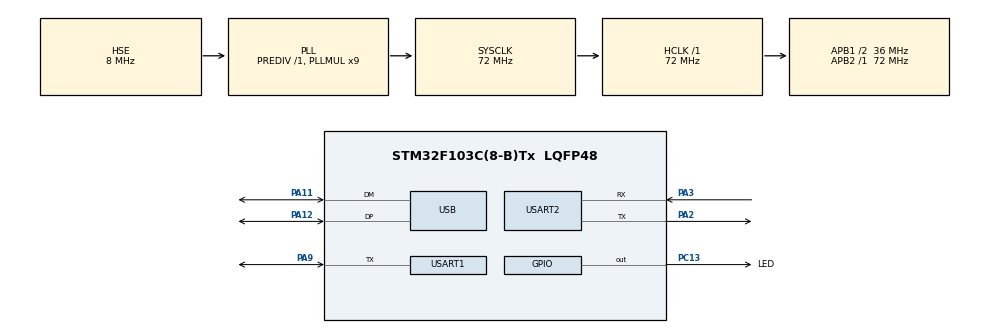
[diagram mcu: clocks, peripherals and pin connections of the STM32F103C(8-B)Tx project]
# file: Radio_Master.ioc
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Dma.Request0=USART1_RX
Dma.Request1=USART1_TX
Dma.USART1_RX.0.Direction=DMA_PERIPH_TO_MEMORY
Dma.USART1_RX.0.Instance=DMA1_Channel5
Dma.USART1_RX.0.MemDataAlignment=DMA_MDATAALIGN_BYTE
Dma.USART1_RX.0.MemInc=DMA_MINC_ENABLE
Dma.USART1_RX.0.Mode=DMA_CIRCULAR
Dma.USART1_RX.0.PeriphDataAlignment=DMA_PDATAALIGN_BYTE
Dma.USART1_RX.0.PeriphInc=DMA_PINC_DISABLE
Dma.USART1_RX.0.Priority=DMA_PRIORITY_LOW
Dma.USART1_TX.1.Direction=DMA_MEMORY_TO_PERIPH
Dma.USART1_TX.1.Instance=DMA1_Channel4
Dma.USART1_TX.1.MemDataAlignment=DMA_MDATAALIGN_BYTE
Dma.USART1_TX.1.MemInc=DMA_MINC_ENABLE
Dma.USART1_TX.1.Mode=DMA_NORMAL
Dma.USART1_TX.1.PeriphDataAlignment=DMA_PDATAALIGN_BYTE
Dma.USART1_TX.1.PeriphInc=DMA_PINC_DISABLE
Dma.USART1_TX.1.Priority=DMA_PRIORITY_LOW
FREERTOS.Tasks01=defaultTask,24,128,StartDefaultTask,Default,NULL,Dynamic,NULL,NULL;CRSF_task,8,128,CRSF_task_Entry,Default,NULL,Dynamic,NULL,NULL
FREERTOS.configUSE_NEWLIB_REENTRANT=1
Mcu.Family=STM32F1
Mcu.Name=STM32F103C(8-B)Tx
Mcu.Package=LQFP48
NVIC.DMA1_Channel4_IRQn=true\:5\:0\:false\:false\:true\:true\:false\:true\:true
NVIC.DMA1_Channel5_IRQn=true\:5\:0\:false\:false\:true\:true\:false\:true\:true
NVIC.PriorityGroup=NVIC_PRIORITYGROUP_4
NVIC.TIM2_IRQn=true\:15\:0\:false\:false\:true\:false\:false\:true\:true
NVIC.TimeBase=TIM2_IRQn
NVIC.TimeBaseIP=TIM2
NVIC.USART1_IRQn=true\:5\:0\:false\:false\:true\:true\:false\:true\:true
NVIC.USB_LP_CAN1_RX0_IRQn=true\:5\:0\:false\:false\:true\:true\:false\:true\:true
PA11.Mode=Device
PA11.Signal=USB_DM
PA12.Mode=Device
PA12.Signal=USB_DP
PA13.Mode=Serial_Wire
PA13.Signal=SYS_JTMS-SWDIO
PA14.Mode=Serial_Wire
PA14.Signal=SYS_JTCK-SWCLK
PA2.Mode=Asynchronous
PA2.Signal=USART2_TX
PA3.Mode=Asynchronous
PA3.Signal=USART2_RX
PA9.Mode=Half_duplex(single_wire_mode)
PA9.Signal=USART1_TX
PC13-TAMPER-RTC.GPIO_Label=LED
PC13-TAMPER-RTC.Signal=GPIO_Output
PC14-OSC32_IN.Mode=LSE-External-Oscillator
PC14-OSC32_IN.Signal=RCC_OSC32_IN
PC15-OSC32_OUT.Mode=LSE-External-Oscillator
PC15-OSC32_OUT.Signal=RCC_OSC32_OUT
PD0-OSC_IN.Mode=HSE-External-Oscillator
PD0-OSC_IN.Signal=RCC_OSC_IN
PD1-OSC_OUT.Mode=HSE-External-Oscillator
PD1-OSC_OUT.Signal=RCC_OSC_OUT
ProjectManager.HeapSize=0x200
ProjectManager.StackSize=0x400
ProjectManager.TargetToolchain=CMake
RCC.AHBFreq_Value=72000000
RCC.APB1CLKDivider=RCC_HCLK_DIV2
RCC.APB1Freq_Value=36000000
RCC.APB1TimFreq_Value=72000000
RCC.APB2Freq_Value=72000000
RCC.APB2TimFreq_Value=72000000
RCC.HCLKFreq_Value=72000000
RCC.PLLMUL=RCC_PLL_MUL9
RCC.SYSCLKFreq_VALUE=72000000
RCC.SYSCLKSource=RCC_SYSCLKSOURCE_PLLCLK
RCC.USBFreq_Value=48000000
RCC.USBPrescaler=RCC_USBCLKSOURCE_PLL_DIV1_5
USART1.BaudRate=400000
USART1.VirtualMode=VM_ASYNC
USART2.VirtualMode=VM_ASYNC
USB_DEVICE.CLASS_NAME_FS=CDC
USB_DEVICE.VirtualMode=Cdc
USB_DEVICE.VirtualModeFS=Cdc_FS
VP_FREERTOS_VS_CMSIS_V2.Mode=CMSIS_V2
VP_SYS_VS_tim2.Mode=TIM2
VP_USB_DEVICE_VS_USB_DEVICE_CDC_FS.Mode=CDC_FS
board=custom

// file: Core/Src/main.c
/* USER CODE BEGIN Header */
/**
  ******************************************************************************
  * @file           : main.c
  * @brief          : Main program body
  ******************************************************************************
  * @attention
  *
  * Copyright (c) 2026 STMicroelectronics.
  * All rights reserved.
  *
  * This software is licensed under terms that can be found in the LICENSE file
  * in the root directory of this software component.
  * If no LICENSE file comes with this software, it is provided AS-IS.
  *
  ******************************************************************************
  */
/* USER CODE END Header */
#include "main.h"
#include "cmsis_os.h"
#include "stm32f1xx_hal_gpio.h"
#include "usb_device.h"

/* USER CODE BEGIN Includes */
#include "crsf.h"
/* USER CODE END Includes */

UART_HandleTypeDef huart1;
UART_HandleTypeDef huart2;
DMA_HandleTypeDef hdma_usart1_rx;
DMA_HandleTypeDef hdma_usart1_tx;

/* Definitions for defaultTask */
osThreadId_t defaultTaskHandle;
const osThreadAttr_t defaultTask_attributes = {
  .name = "defaultTask",
  .stack_size = 128 * 4,
  .priority = (osPriority_t) osPriorityNormal,
};
/* Definitions for CRSF_task */
osThreadId_t CRSF_taskHandle;
const osThreadAttr_t CRSF_task_attributes = {
  .name = "CRSF_task",
  .stack_size = 256 * 4,
  .priority = (osPriority_t) osPriorityHigh,
};

void SystemClock_Config(void);
static void MX_GPIO_Init(void);
static void MX_DMA_Init(void);
static void MX_USART1_UART_Init(void);
static void MX_USART2_UART_Init(void);
void StartDefaultTask(void *argument);
void CRSF_task_Entry(void *argument);

int main(void)
{

  /* MCU Configuration--------------------------------------------------------*/

  /* Reset of all peripherals, Initializes the Flash interface and the Systick. */
  HAL_Init();

  /* Configure the system clock */
  SystemClock_Config();

  /* Initialize all configured peripherals */
  MX_GPIO_Init();
  MX_DMA_Init();
  MX_USART1_UART_Init();
  MX_USART2_UART_Init();

  /* Init scheduler */
  osKernelInitialize();

  /* Create the thread(s) */
  /* creation of defaultTask */
  defaultTaskHandle = osThreadNew(StartDefaultTask, NULL, &defaultTask_attributes);

  /* creation of CRSF_task */
  CRSF_taskHandle  = osThreadNew(CRSF_task_Entry,  NULL, &CRSF_task_attributes);

  /* Start scheduler */
  osKernelStart();

  /* We should never get here as control is now taken by the scheduler */

  /* Infinite loop */
  while (1)
  {

  }
}

void SystemClock_Config(void)
{
  RCC_OscInitTypeDef RCC_OscInitStruct = {0};
  RCC_ClkInitTypeDef RCC_ClkInitStruct = {0};
  RCC_PeriphCLKInitTypeDef PeriphClkInit = {0};

  /** Initializes the RCC Oscillators according to the specified parameters
  * in the RCC_OscInitTypeDef structure.
  */
  RCC_OscInitStruct.OscillatorType = RCC_OSCILLATORTYPE_HSE;
  RCC_OscInitStruct.HSEState = RCC_HSE_ON;
  RCC_OscInitStruct.HSEPredivValue = RCC_HSE_PREDIV_DIV1;
  RCC_OscInitStruct.HSIState = RCC_HSI_ON;
  RCC_OscInitStruct.PLL.PLLState = RCC_PLL_ON;
  RCC_OscInitStruct.PLL.PLLSource = RCC_PLLSOURCE_HSE;
  RCC_OscInitStruct.PLL.PLLMUL = RCC_PLL_MUL9;
  if (HAL_RCC_OscConfig(&RCC_OscInitStruct) != HAL_OK)
  {
    Error_Handler();
  }

  /** Initializes the CPU, AHB and APB buses clocks
  */
  RCC_ClkInitStruct.ClockType = RCC_CLOCKTYPE_HCLK|RCC_CLOCKTYPE_SYSCLK
                              |RCC_CLOCKTYPE_PCLK1|RCC_CLOCKTYPE_PCLK2;
  RCC_ClkInitStruct.SYSCLKSource = RCC_SYSCLKSOURCE_PLLCLK;
  RCC_ClkInitStruct.AHBCLKDivider = RCC_SYSCLK_DIV1;
  RCC_ClkInitStruct.APB1CLKDivider = RCC_HCLK_DIV2;
  RCC_ClkInitStruct.APB2CLKDivider = RCC_HCLK_DIV1;

  if (HAL_RCC_ClockConfig(&RCC_ClkInitStruct, FLASH_LATENCY_2) != HAL_OK)
  {
    Error_Handler();
  }
  PeriphClkInit.PeriphClockSelection = RCC_PERIPHCLK_USB;
  PeriphClkInit.UsbClockSelection = RCC_USBCLKSOURCE_PLL_DIV1_5;
  if (HAL_RCCEx_PeriphCLKConfig(&PeriphClkInit) != HAL_OK)
  {
    Error_Handler();
  }
}

static void MX_USART1_UART_Init(void)
{

  huart1.Instance = USART1;
  huart1.Init.BaudRate = 400000;
  huart1.Init.WordLength = UART_WORDLENGTH_8B;
  huart1.Init.StopBits = UART_STOPBITS_1;
  huart1.Init.Parity = UART_PARITY_NONE;
  huart1.Init.Mode = UART_MODE_TX_RX;
  huart1.Init.HwFlowCtl = UART_HWCONTROL_NONE;
  huart1.Init.OverSampling = UART_OVERSAMPLING_16;
  if (HAL_HalfDuplex_Init(&huart1) != HAL_OK)
  {
    Error_Handler();
  }

}

static void MX_USART2_UART_Init(void)
{

  huart2.Instance = USART2;
  huart2.Init.BaudRate = 115200;
  huart2.Init.WordLength = UART_WORDLENGTH_8B;
  huart2.Init.StopBits = UART_STOPBITS_1;
  huart2.Init.Parity = UART_PARITY_NONE;
  huart2.Init.Mode = UART_MODE_TX_RX;
  huart2.Init.HwFlowCtl = UART_HWCONTROL_NONE;
  huart2.Init.OverSampling = UART_OVERSAMPLING_16;
  if (HAL_UART_Init(&huart2) != HAL_OK)
  {
    Error_Handler();
  }

}

static void MX_DMA_Init(void)
{

  /* DMA controller clock enable */
  __HAL_RCC_DMA1_CLK_ENABLE();

  /* DMA interrupt init */
  /* DMA1_Channel4_IRQn interrupt configuration */
  HAL_NVIC_SetPriority(DMA1_Channel4_IRQn, 5, 0);
  HAL_NVIC_EnableIRQ(DMA1_Channel4_IRQn);
  /* DMA1_Channel5_IRQn interrupt configuration */
  HAL_NVIC_SetPriority(DMA1_Channel5_IRQn, 5, 0);
  HAL_NVIC_EnableIRQ(DMA1_Channel5_IRQn);

}

static void MX_GPIO_Init(void)
{
  GPIO_InitTypeDef GPIO_InitStruct = {0};

  /* GPIO Ports Clock Enable */
  __HAL_RCC_GPIOC_CLK_ENABLE();
  __HAL_RCC_GPIOD_CLK_ENABLE();
  __HAL_RCC_GPIOA_CLK_ENABLE();

  /*Configure GPIO pin Output Level */
  HAL_GPIO_WritePin(LED_GPIO_Port, LED_Pin, GPIO_PIN_RESET);

  /*Configure GPIO pin : LED_Pin */
  GPIO_InitStruct.Pin = LED_Pin;
  GPIO_InitStruct.Mode = GPIO_MODE_OUTPUT_PP;
  GPIO_InitStruct.Pull = GPIO_NOPULL;
  GPIO_InitStruct.Speed = GPIO_SPEED_FREQ_LOW;
  HAL_GPIO_Init(LED_GPIO_Port, &GPIO_InitStruct);

}

void StartDefaultTask(void *argument)
{
  /* init code for USB_DEVICE */
  MX_USB_DEVICE_Init();
  /* USER CODE BEGIN 5 */
  /* Infinite loop */
  for(;;)
  {
    HAL_GPIO_TogglePin(LED_GPIO_Port, LED_Pin);
    osDelay(100);
  }
  /* USER CODE END 5 */
}

void CRSF_task_Entry(void *argument)
{
  /* USER CODE BEGIN CRSF_task_Entry */
  crsf_init(&huart1);
  crsf_run(argument);
  /* USER CODE END CRSF_task_Entry */
}

void HAL_TIM_PeriodElapsedCallback(TIM_HandleTypeDef *htim)
{
  if (htim->Instance == TIM2)
  {
    HAL_IncTick();
  }
}

void Error_Handler(void)
{
  __disable_irq();
  while (1)
  {
  }
}
